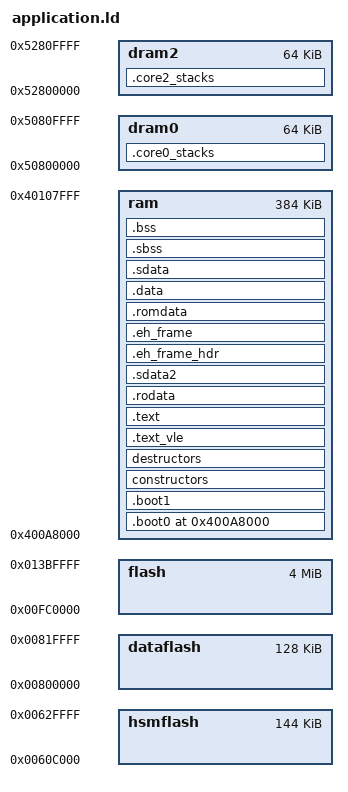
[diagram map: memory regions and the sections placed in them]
/****************************************************************************
*
* Copyright © 2016-2019 STMicroelectronics - All Rights Reserved
*
* This software is licensed under SLA0098 terms that can be found in the
* DM00779817_1_0.pdf file in the licenses directory of this software product.
* 
* THIS SOFTWARE IS DISTRIBUTED "AS IS," AND ALL WARRANTIES ARE DISCLAIMED, 
* INCLUDING MERCHANTABILITY AND FITNESS FOR A PARTICULAR PURPOSE.
*
*****************************************************************************/

/*
 * This file is automatically generated and can be overwritten, do no change
 * this file manually.
 */

/*
 * SPC58ECxx memory setup.
 */

__irq_stack_size__            = 0;
__process_stack_size__        = 4096;
__core0_irq_stack_size__      = 0;
__core0_process_stack_size__  = 2048;



MEMORY
{
    hsmflash    : org = 0x0060C000, len = 144k
    dataflash   : org = 0x00800000, len = 128k
    flash       : org = 0x00FC0000, len = 4M  
    ram         : org = 0x400A8000, len = 512k - 128k
    dram0       : org = 0x50800000, len = 64k
    dram2       : org = 0x52800000, len = 64k
}

ENTRY(_reset_address2)

/*
 * Derived constants.
 */
__flash_size__          = LENGTH(flash);
__flash_start__         = ORIGIN(flash);
__flash_end__           = ORIGIN(flash) + LENGTH(flash);

__ram_size__            = LENGTH(ram);
__ram_start__           = ORIGIN(ram);
__ram_end__             = ORIGIN(ram) + LENGTH(ram);

__dram0_size__          = LENGTH(dram0);
__dram0_start__         = ORIGIN(dram0);
__dram0_end__           = ORIGIN(dram0) + LENGTH(dram0);

__dram2_size__          = LENGTH(dram2);
__dram2_start__         = ORIGIN(dram2);
__dram2_end__           = ORIGIN(dram2) + LENGTH(dram2);


SECTIONS
{
    . = ORIGIN(ram);
    .boot0 : ALIGN(16) SUBALIGN(16)
    {
        KEEP(*(.boot))
        KEEP(*(.handlers))
        KEEP(*(.crt0))
    } > ram

    .boot1 : ALIGN(16) SUBALIGN(16)
    {
        /* The IVPR registers require a 256 bytes alignment.*/
        . = ALIGN(0x100);
        __ivpr0_base__ = .;
        KEEP(*(.core0_ivors))

        /* The IVPR registers require a 256 bytes alignment.*/
        . = ALIGN(0x100);
        __ivpr2_base__ = .;
        KEEP(*(.core2_ivors))

        /* The vectors table requires a 4kB alignment.*/
        . = ALIGN(0x1000);
        KEEP(*(.vectors))
    } > ram

    constructors : ALIGN(4) SUBALIGN(4)
    {
        PROVIDE(__init_array_start = .);
        KEEP(*(SORT(.init_array.*)))
        KEEP(*(.init_array))
        PROVIDE(__init_array_end = .);
    } > ram

    destructors : ALIGN(4) SUBALIGN(4)
    {
        PROVIDE(__fini_array_start = .);
        KEEP(*(.fini_array))
        KEEP(*(SORT(.fini_array.*)))
        PROVIDE(__fini_array_end = .);
    } > ram

    .text_vle : ALIGN(16) SUBALIGN(16)
    {
        *(.text_vle)
        *(.text_vle.*)
        *(.gnu.linkonce.t_vle.*)
    } > ram

    .text : ALIGN(16) SUBALIGN(16)
    {
        *(.text)
        *(.text.*)
        *(.gnu.linkonce.t.*)
    } > ram

    .rodata : ALIGN(16) SUBALIGN(16)
    {
        *(.glue_7t)
        *(.glue_7)
        *(.gcc*)
        *(.rodata)
        *(.rodata.*)
        *(.rodata1)
    } > ram

    .sdata2 : ALIGN(16) SUBALIGN(16)
    {
        __sdata2_start__ = . + 0x8000;
        *(.sdata2)
        *(.sdata2.*)
        *(.gnu.linkonce.s2.*)
        *(.sbss2)
        *(.sbss2.*)
        *(.gnu.linkonce.sb2.*)
    } > ram

    .eh_frame_hdr :
    {
        *(.eh_frame_hdr)
    } > ram

    .eh_frame : ONLY_IF_RO
    {
        *(.eh_frame)
    } > ram

    .romdata : ALIGN(16) SUBALIGN(16)
    {
        __romdata_start__ = .;
    } > ram

    .core0_stacks : ALIGN(16) SUBALIGN(16)
    {
        . = ALIGN(8);
        __core0_irq_stack_base__ = .;
        . += __core0_irq_stack_size__;
        . = ALIGN(8);
        __core0_irq_stack_end__ = .;
        __core0_process_stack_base__ = .;
        __core0_main_thread_stack_base__ = .;
        . += __core0_process_stack_size__;
        . = ALIGN(8);
        __core0_process_stack_end__ = .;
        __core0_main_thread_stack_end__ = .;
    } > dram0

    .core2_stacks : ALIGN(16) SUBALIGN(16)
    {
        . = ALIGN(8);
        __irq_stack_base__ = .;
        . += __irq_stack_size__;
        . = ALIGN(8);
        __irq_stack_end__ = .;
        __process_stack_base__ = .;
        __main_thread_stack_base__ = .;
        . += __process_stack_size__;
        . = ALIGN(8);
        __process_stack_end__ = .;
        __main_thread_stack_end__ = .;
    } > dram2

    .data :
    {
        . = ALIGN(4);
        __data_start__ = .;
        *(.data)
        *(.data.*)
        *(.gnu.linkonce.d.*)
    } > ram

    .sdata :
    {
        . = ALIGN(4);
        __sdata_start__ = . + 0x8000;
        *(.sdata)
        *(.sdata.*)
        *(.gnu.linkonce.s.*)
        __data_end__ = .;
    } > ram

    .sbss :
    {
        __bss_start__ = .;
        *(.sbss)
        *(.sbss.*)
        *(.gnu.linkonce.sb.*)
        *(.scommon)
    } > ram

    .bss :
    {
        *(.bss)
        *(.bss.*)
        *(.gnu.linkonce.b.*)
        *(COMMON)
        __bss_end__ = .;
    } > ram

    __heap_base__   = __bss_end__;
    __heap_end__    = __ram_end__;
}
